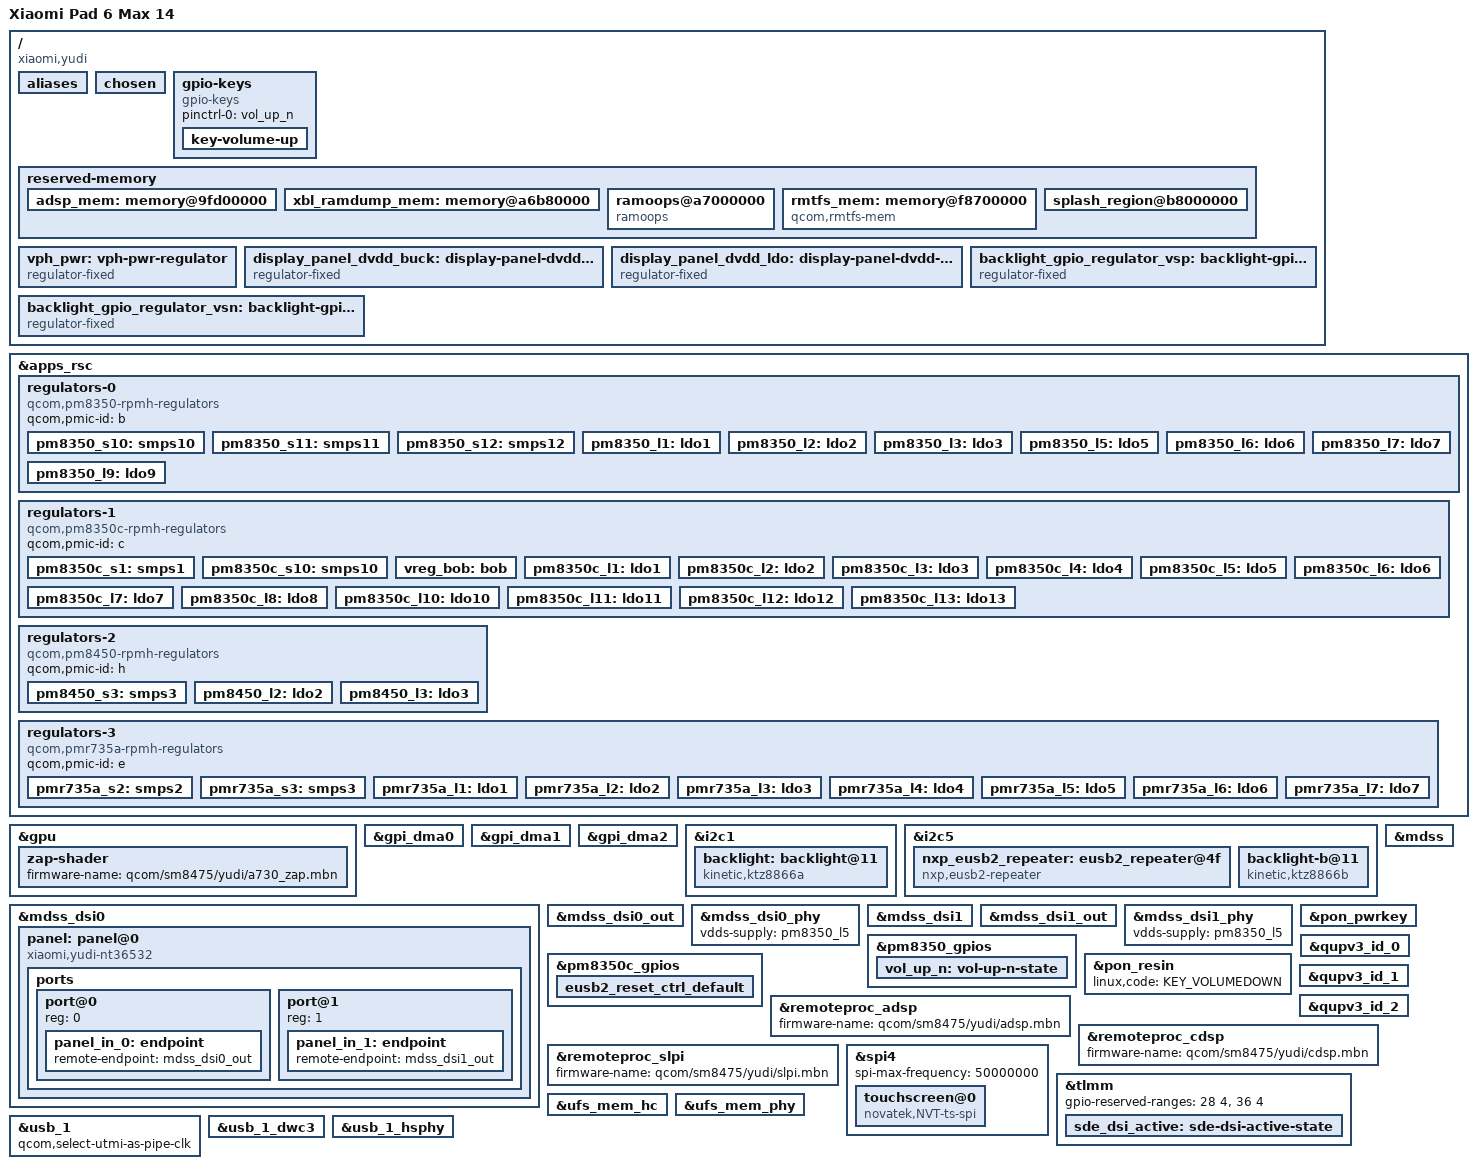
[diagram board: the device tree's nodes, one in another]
// SPDX-License-Identifier: GPL-2.0-only
/*
 * Copyright (c) 2025, The Linux Foundation. All rights reserved.
 * Copyright (c) 2025, Sophie 'Tyalie' Friedrich <kernel@flowerpot.me>
 */
/dts-v1/;

#include <dt-bindings/arm/qcom,ids.h>
#include <dt-bindings/pinctrl/qcom,pmic-gpio.h>
#include <dt-bindings/regulator/qcom,rpmh-regulator.h>
#include <dt-bindings/leds/common.h>
#include <dt-bindings/interrupt-controller/irq.h>

#include "sm8475.dtsi"
#include "pm8350.dtsi"
#include "pm8350b.dtsi"
#include "pm8350c.dtsi"
#include "pm8450.dtsi"
#include "pmk8350.dtsi"
#include "pmr735a.dtsi"

/delete-node/ &adsp_mem;
/delete-node/ &rmtfs_mem;
/delete-node/ &xbl_ramdump_mem;
/delete-node/ &xbl_sc_mem;

/ {
	model = "Xiaomi Pad 6 Max 14";
	compatible = "xiaomi,yudi", "qcom,sm8475";
	chassis-type = "tablet";

	aliases {
	};

	chosen {
		#address-cells = <2>;
		#size-cells = <2>;
		ranges;

		bootargs = "PMOS_NOSPLASH earlycon clk_ignore_unused pd_ignore_unused console=tty0";

	};


	gpio-keys {
		compatible = "gpio-keys";

		pinctrl-0 = <&vol_up_n>;
		pinctrl-names = "default";

		key-volume-up {
			label = "Volume Up";
			linux,code = <KEY_VOLUMEUP>;
			gpios = <&pm8350_gpios 6 GPIO_ACTIVE_LOW>;
			debounce-interval = <32>;
			linux,can-disable;
			wakeup-source;
		};
	};

	reserved-memory {
		adsp_mem: memory@9fd00000 {
			reg = <0x0 0x9fd00000 0x0 0x3100000>;
			no-map;
		};

		xbl_ramdump_mem: memory@a6b80000 {
			reg = <0x0 0xa6b80000 0x0 0x280000>;
			no-map;
		};

		ramoops@a7000000 {
			compatible = "ramoops";
			reg = <0x0 0xa7000000 0x0 0x400000>;

			record-size = <0x200000>;
			pmsg-size = <0x200000>;
			console-size = <0x200000>;
			no-map;
		};

		rmtfs_mem: memory@f8700000 {
			compatible = "qcom,rmtfs-mem";
			reg = <0x0 0xf8700000 0x0 0x280000>;
			no-map;

			qcom,client-id = <1>;
			qcom,vmid = <QCOM_SCM_VMID_MSS_MSA>;
		};


		splash_region@b8000000 {
			reg = <0x0 0xb8000000 0x0 0x2b00000>;
			no-map;
		};
	};

	vph_pwr: vph-pwr-regulator {
		compatible = "regulator-fixed";
		regulator-name = "vph_pwr";
		regulator-min-microvolt = <3700000>;
		regulator-max-microvolt = <3700000>;

		regulator-always-on;
		regulator-boot-on;
	};

	display_panel_dvdd_buck: display-panel-dvdd-buck {
		compatible = "regulator-fixed";
		regulator-name = "display_panel_dvdd_buck";
		regulator-min-microvolt = <(1300 * 1000)>;
		regulator-max-microvolt = <(1300 * 1000)>;
		gpio = <&tlmm 2 GPIO_ACTIVE_HIGH>;
		enable-active-high;
		regulator-boot-on;

		regulator-always-on;
	};

	display_panel_dvdd_ldo: display-panel-dvdd-ldo {
		compatible = "regulator-fixed";
		regulator-name = "display_panel_dvdd_ldo";
		regulator-min-microvolt = <(1300 * 1000)>;
		regulator-max-microvolt = <(1300 * 1000)>;
		gpio = <&tlmm 93 GPIO_ACTIVE_HIGH>;
		enable-active-high;
		regulator-boot-on;

		regulator-always-on;
	};

	backlight_gpio_regulator_vsp: backlight-gpio-reg-vsp {
		compatible = "regulator-fixed";
		regulator-name = "backlight_gpio_vsp";
		regulator-min-microvolt = <5500000>;
		regulator-max-microvolt = <5500000>;
		regulator-enable-ramp-delay = <233>;
		gpio = <&tlmm 66 GPIO_ACTIVE_HIGH>;
		enable-active-high;
		regulator-boot-on;

		regulator-always-on;
	};

	backlight_gpio_regulator_vsn: backlight-gpio-reg-vsn {
		compatible = "regulator-fixed";
		regulator-name = "backlight_gpio_vsn";
		regulator-min-microvolt = <5500000>;
		regulator-max-microvolt = <5500000>;
		regulator-enable-ramp-delay = <233>;
		gpio = <&tlmm 53 GPIO_ACTIVE_HIGH>;
		enable-active-high;
		regulator-boot-on;

		regulator-always-on;
	};
};

&apps_rsc {
	regulators-0 {
		compatible = "qcom,pm8350-rpmh-regulators";
		qcom,pmic-id = "b";

		/*
		vdd-s1-supply = <&vph_pwr>;
		vdd-s2-supply = <&vph_pwr>;
		vdd-s3-supply = <&vph_pwr>;
		vdd-s4-supply = <&vph_pwr>;
		vdd-s5-supply = <&vph_pwr>;
		vdd-s6-supply = <&vph_pwr>;
		vdd-s7-supply = <&vph_pwr>;
		vdd-s8-supply = <&vph_pwr>;
		vdd-s9-supply = <&vph_pwr>;
		vdd-s10-supply = <&vph_pwr>;
		vdd-s11-supply = <&vph_pwr>;
		vdd-s12-supply = <&vph_pwr>;

		vdd-l1-l4-supply = <&pm8350_s11>;
		vdd-l2-l7-supply = <&vreg_bob>;
		vdd-l3-l5-supply = <&pm8350_s11>;
		vdd-l6-l9-l10-supply = <&pm8350_s12>;
		*/

		/*
		 * ARC regulators:
		 * s5 - gfx.lvl
		 * l8 - lcx.lvl
		 */

		pm8350_s10: smps10 {
			regulator-name = "pm8350_s10";
			regulator-min-microvolt = <1800000>;
			regulator-max-microvolt = <1800000>;
		};

		pm8350_s11: smps11 {
			regulator-name = "pm8350_s11";
			regulator-min-microvolt = <382000>;
			regulator-max-microvolt = <1170000>;
		};

		pm8350_s12: smps12 {
			regulator-name = "pm8350_s12";
			regulator-min-microvolt = <1224000>;
			regulator-max-microvolt = <2040000>;
		};

		pm8350_l1: ldo1 {
			regulator-name = "pm8350_l1";
			regulator-min-microvolt = <830000>;
			regulator-max-microvolt = <920000>;
			regulator-initial-mode = <RPMH_REGULATOR_MODE_HPM>;
		};

		pm8350_l2: ldo2 {
			regulator-name = "pm8350_l2";
			regulator-min-microvolt = <2700000>;
			regulator-max-microvolt = <3300000>;
			regulator-initial-mode = <RPMH_REGULATOR_MODE_HPM>;
		};

		pm8350_l3: ldo3 {
			regulator-name = "pm8350_l3";
			regulator-min-microvolt = <870000>;
			regulator-max-microvolt = <970000>;
			regulator-initial-mode = <RPMH_REGULATOR_MODE_HPM>;
		};

		pm8350_l5: ldo5 {
			regulator-name = "pm8350_l5";
			regulator-min-microvolt = <720000>;
			regulator-max-microvolt = <958000>;
			regulator-initial-mode = <RPMH_REGULATOR_MODE_HPM>;
		};

		pm8350_l6: ldo6 {
			regulator-name = "pm8350_l6";
			regulator-min-microvolt = <1200000>;
			regulator-max-microvolt = <1216000>;
			regulator-initial-mode = <RPMH_REGULATOR_MODE_HPM>;
		};

		pm8350_l7: ldo7 {
			regulator-name = "pm8350_l7";
			regulator-min-microvolt = <2400000>;
			regulator-max-microvolt = <3544000>;
			regulator-initial-mode = <RPMH_REGULATOR_MODE_HPM>;
		};

		pm8350_l9: ldo9 {
			regulator-name = "pm8350_l9";
			regulator-min-microvolt = <1200000>;
			regulator-max-microvolt = <1304000>;
			regulator-initial-mode = <RPMH_REGULATOR_MODE_HPM>;
		};
	};

	regulators-1 {
		compatible = "qcom,pm8350c-rpmh-regulators";
		qcom,pmic-id = "c";

		/*
		vdd-s1-supply = <&vph_pwr>;
		vdd-s2-supply = <&vph_pwr>;
		vdd-s3-supply = <&vph_pwr>;
		vdd-s4-supply = <&vph_pwr>;
		vdd-s5-supply = <&vph_pwr>;
		vdd-s6-supply = <&vph_pwr>;
		vdd-s7-supply = <&vph_pwr>;
		vdd-s8-supply = <&vph_pwr>;
		vdd-s9-supply = <&vph_pwr>;
		vdd-s10-supply = <&vph_pwr>;

		vdd-l1-l12-supply = <&pm8350c_s1>;
		vdd-l2-l8-supply = <&pm8350c_s1>;
		vdd-l3-l4-l5-l7-l13-supply = <&vreg_bob>;
		vdd-l6-l9-l11-supply = <&vreg_bob>;
		vdd-l10-supply = <&pm8350_s12>;

		vdd-bob-supply = <&vph_pwr>;
		*/

		/*
		 * ARC regulators:
		 * s2 - mxc.lvl
		 * s4 - mss.lvl
		 * s6 - cx.lvl
		 */

		pm8350c_s1: smps1 {
			regulator-name = "pm8350c_s1";
			regulator-min-microvolt = <1800000>;
			regulator-max-microvolt = <2024000>;
		};

		pm8350c_s10: smps10 {
			regulator-name = "pm8350c_s10";
			regulator-min-microvolt = <1052000>;
			regulator-max-microvolt = <1170000>;
		};

		vreg_bob: bob {
			regulator-name = "vreg_bob";
			regulator-min-microvolt = <3008000>;
			regulator-max-microvolt = <3960000>;
			regulator-initial-mode = <RPMH_REGULATOR_MODE_AUTO>;
		};

		pm8350c_l1: ldo1 {
			regulator_name = "pm8350c_l1";
			regulator-min-microvolt = <1800000>;
			regulator-max-microvolt = <1800000>;
			regulator-initial-mode = <RPMH_REGULATOR_MODE_HPM>;
		};

		pm8350c_l2: ldo2 {
			regulator-name = "pm8350c_l2";
			regulator-min-microvolt = <1800000>;
			regulator-max-microvolt = <1980000>;
			regulator-initial-mode = <RPMH_REGULATOR_MODE_HPM>;
		};

		pm8350c_l3: ldo3 {
			regulator-name = "pm8350c_l3";
			regulator-min-microvolt = <2700000>;
			regulator-max-microvolt = <3544000>;
			regulator-initial-mode = <RPMH_REGULATOR_MODE_HPM>;
			regulator-boot-on;
			regulator-always-on;
		};

		pm8350c_l4: ldo4 {
			regulator-name = "pm8350c_l4";
			regulator-min-microvolt = <1620000>;
			regulator-max-microvolt = <3300000>;
			regulator-initial-mode = <RPMH_REGULATOR_MODE_HPM>;
		};

		pm8350c_l5: ldo5 {
			regulator-name = "pm8350c_l5";
			regulator-min-microvolt = <1620000>;
			regulator-max-microvolt = <3300000>;
			regulator-initial-mode = <RPMH_REGULATOR_MODE_HPM>;
		};

		pm8350c_l6: ldo6 {
			regulator-name = "pm8350c_l6";
			regulator-min-microvolt = <1800000>;
			regulator-max-microvolt = <3544000>;
			regulator-initial-mode = <RPMH_REGULATOR_MODE_HPM>;
		};

		pm8350c_l7: ldo7 {
			regulator-name = "pm8350c_l7";
			regulator-min-microvolt = <3000000>;
			regulator-max-microvolt = <3544000>;
			regulator-initial-mode = <RPMH_REGULATOR_MODE_HPM>;
		};

		pm8350c_l8: ldo8 {
			regulator-name = "pm8350c_l8";
			regulator-min-microvolt = <1800000>;
			regulator-max-microvolt = <2000000>;
			regulator-initial-mode = <RPMH_REGULATOR_MODE_HPM>;
		};

//		pm8350c_l9: ldo9 {
//			regulator-name = "pm8350c_l9";
//			regulator-min-microvolt = <3300000>;
//			regulator-max-microvolt = <3300000>;
//			regulator-initial-mode = <RPMH_REGULATOR_MODE_HPM>;
//		};

		pm8350c_l10: ldo10 {
			regulator-name = "pm8350c_l10";
			regulator-min-microvolt = <1200000>;
			regulator-max-microvolt = <1304000>;
			regulator-initial-mode = <RPMH_REGULATOR_MODE_HPM>;
		};

		pm8350c_l11: ldo11 {
			regulator-name = "pm8350c_l11";
			regulator-min-microvolt = <2400000>;
			regulator-max-microvolt = <3008000>;
			regulator-initial-mode = <RPMH_REGULATOR_MODE_HPM>;
		};

		pm8350c_l12: ldo12 {
			regulator-name = "pm8350c_l12";
			regulator-min-microvolt = <1800000>;
			regulator-max-microvolt = <1980000>;
			regulator-initial-mode = <RPMH_REGULATOR_MODE_HPM>;
		};

		pm8350c_l13: ldo13 {
			regulator-name = "pm8350c_l13";
			regulator-min-microvolt = <2700000>;
			regulator-max-microvolt = <3544000>;
			regulator-initial-mode = <RPMH_REGULATOR_MODE_HPM>;
		};
	};

	regulators-2 {
		compatible = "qcom,pm8450-rpmh-regulators";
		qcom,pmic-id = "h";

		/*
		vdd-s1-supply = <&vph_pwr>;
		vdd-s2-supply = <&vph_pwr>;
		vdd-s3-supply = <&vph_pwr>;
		vdd-s4-supply = <&vph_pwr>;
		vdd-s5-supply = <&vph_pwr>;
		vdd-s6-supply = <&vph_pwr>;

		vdd-l2-supply = <&vreg_bob>;
		vdd-l3-supply = <&vreg_bob>;
		vdd-l4-supply = <&vreg_bob>;
		*/

		/*
		 * ARC regulators:
		 * S2 - ebi.lvl
		 * S4 - mmcx.lvl
		 * S6 - mx.lvl
		 * L1 - lmx.lvl
		 */

		pm8450_s3: smps3 {
			regulator-name = "pm8450_s3";
			regulator-min-microvolt = <470000>;
			regulator-max-microvolt = <570000>;
		};

		pm8450_l2: ldo2 {
			regulator-name = "pm8450_l2";
			regulator-min-microvolt = <820000>;
			regulator-max-microvolt = <958000>;
			regulator-initial-mode = <RPMH_REGULATOR_MODE_HPM>;
		};

		pm8450_l3: ldo3 {
			regulator-name = "pm8450_l3";
			regulator-min-microvolt = <866000>;
			regulator-max-microvolt = <958000>;
			regulator-initial-mode = <RPMH_REGULATOR_MODE_HPM>;
		};
	};

	regulators-3 {
		compatible = "qcom,pmr735a-rpmh-regulators";
		qcom,pmic-id = "e";

		/*
		vdd-s1-supply = <&vph_pwr>;
		vdd-s2-supply = <&vph_pwr>;
		vdd-s3-supply = <&vph_pwr>;

		vdd-l1-l2-supply = <&pmr735a_s2>;
		vdd-l3-supply = <&pmr735a_s1>;
		vdd-l4-supply = <&pm8350c_s1>;
		vdd-l5-l6-supply = <&pm8350c_s1>;
		vdd-l7-bob-supply = <&vreg_bob>;
		*/

		pmr735a_s2: smps2 {
			regulator-name = "pmr735a_s2";
			regulator-min-microvolt = <500000>;
			regulator-max-microvolt = <1040000>;
		};

		pmr735a_s3: smps3 {
			regulator-name = "pmr735a_s3";
			regulator-min-microvolt = <300000>;
			regulator-max-microvolt = <2352000>;
		};

		pmr735a_l1: ldo1 {
			regulator-name = "pmr735a_l1";
			regulator-min-microvolt = <800000>;
			regulator-max-microvolt = <880000>;
		};

		pmr735a_l2: ldo2 {
			regulator-name = "pmr735a_l2";
			regulator-min-microvolt = <480000>;
			regulator-max-microvolt = <1200000>;
		};

		pmr735a_l3: ldo3 {
			regulator-name = "pmr735a_l3";
			regulator-min-microvolt = <1200000>;
			regulator-max-microvolt = <1200000>;
		};

		pmr735a_l4: ldo4 {
			regulator-name = "pmr735a_l4";
			regulator-min-microvolt = <1776000>;
			regulator-max-microvolt = <1776000>;
		};

		pmr735a_l5: ldo5 {
			regulator-name = "pmr735a_l5";
			regulator-min-microvolt = <880000>;
			regulator-max-microvolt = <920000>;
		};

		pmr735a_l6: ldo6 {
			regulator-name = "pmr735a_l6";
			regulator-min-microvolt = <1200000>;
			regulator-max-microvolt = <1200000>;
		};

		pmr735a_l7: ldo7 {
			regulator-name = "pmr735a_l7";
			regulator-min-microvolt = <2800000>;
			regulator-max-microvolt = <2800000>;
		};
	};
};

&gpu {
	status = "okay";

	zap-shader {
		firmware-name = "qcom/sm8475/yudi/a730_zap.mbn";
	};
};

&gpi_dma0 {
	status = "okay";
};

&gpi_dma1 {
	status = "okay";
};

&gpi_dma2 {
	status = "okay";
};

&i2c1 {
	status = "okay";

	/* ktz8866@11 ktz,ktz8866b */
	backlight: backlight@11 {
		compatible = "kinetic,ktz8866a";
		reg = <0x11>;
		vddpos-supply = <&backlight_gpio_regulator_vsp>;
		vddneg-supply = <&backlight_gpio_regulator_vsn>;
		enable-gpios = <&tlmm 6 GPIO_ACTIVE_HIGH>;
		current-num-sinks = <5>;
		kinetic,current-ramp-delay-ms = <128>;
		kinetic,led-enable-ramp-delay-ms = <1>;
		kinetic,enable-lcd-bias;

	};

};

&i2c5 {
	status = "okay";

	/* fsa4480@42 qcom,fsa4480-i2c */

	nxp_eusb2_repeater: eusb2_repeater@4f {
		compatible = "nxp,eusb2-repeater";
		reg = <0x4f>;
		vdd18-supply = <&pm8350_s10>;
		vdd3-supply = <&pm8350_l2>;
		reset-gpio = <&pm8350c_gpios 7 GPIO_ACTIVE_HIGH>;
		pinctrl-names = "default";
		pinctrl-0 = <&eusb2_reset_ctrl_default>;
		#phy-cells = <0>;
		qcom,param-override-seq = <0x40 0x06 0x01 0x07 0x65 0x08 0x03 0x0a>;
		qcom,param-override-seq-host = <0x30 0x06 0x00 0x07 0x64 0x08 0x03 0x0a>;
	};

	/* ktz8866@11 ktz,ktz8866b */
	backlight-b@11 {
		compatible = "kinetic,ktz8866b";
		reg = <0x11>;
		vddpos-supply = <&backlight_gpio_regulator_vsp>;
		vddneg-supply = <&backlight_gpio_regulator_vsn>;
		enable-gpios = <&tlmm 6 GPIO_ACTIVE_HIGH>;
		current-num-sinks = <5>;
		kinetic,current-ramp-delay-ms = <128>;
		kinetic,led-enable-ramp-delay-ms = <1>;
		kinetic,enable-lcd-bias;

	};
};

//&i2c9 {
//	clock-frequency = <1000000>;
//	status = "okay";
//
//	/* nq@28 qcom,sn-nci */
//};

//&spi13 {
//	clock-frequency = <50000000>;
//	status = "okay";
//
//	/* ir-spi@0 ir-spi */
//};

//&i2c15 {
//	clock-frequency = <1000000>;
//	status = "okay";
//
//	/* cs35l41@40 cirrus,cs35l41 */
//	/* cs35l41@42 cirrus,cs35l41 */
//};

&mdss {
	status = "okay";
};

&mdss_dsi0 {
	vdda-supply = <&pm8350c_l10>;
	qcom,dual-dsi-mode;
	qcom,sync-dual-dsi;
	qcom,master-dsi;

	status = "okay";

	panel: panel@0 {
		status = "okay";

		compatible = "xiaomi,yudi-nt36532", "novatek,nt36532";
		reg = <0>;

		vddio-supply = <&pm8350c_l2>;
		dvddbuck-supply = <&display_panel_dvdd_buck>;
		dvddldo-supply = <&display_panel_dvdd_ldo>;
		/*enp-supply = <&display_gpio_regulator_vsp>;
		enn-supply = <&display_gpio_regulator_vsn>; FIXME*/

		reset-gpios = <&tlmm 0 GPIO_ACTIVE_LOW>;
		backlight = <&backlight>;

		pinctrl-0 = <&sde_dsi_active>;
		pinctrl-names = "default";

		ports {
			#address-cells = <1>;
			#size-cells = <0>;

			port@0 {
				reg = <0>;
				panel_in_0: endpoint {
					remote-endpoint = <&mdss_dsi0_out>;
				};
			};

			port@1 {
				reg = <1>;
				panel_in_1: endpoint {
					remote-endpoint = <&mdss_dsi1_out>;
				};

			};
		};
	};
};

&mdss_dsi0_out {
	remote-endpoint = <&panel_in_0>;
	data-lanes = <0 1 2 3>;
};

&mdss_dsi0_phy {
	vdds-supply = <&pm8350_l5>;
	status = "okay";
};

&mdss_dsi1 {
	vdda-supply = <&pm8350c_l10>;
	qcom,dual-dsi-mode;
	qcom,sync-dual-dsi;
	assigned-clock-parents = <&mdss_dsi0_phy 0>, <&mdss_dsi0_phy 1>;
	status = "okay";
};

&mdss_dsi1_out {
	remote-endpoint = <&panel_in_1>;
	data-lanes = <0 1 2 3>;
};

&mdss_dsi1_phy {
	vdds-supply = <&pm8350_l5>;
	status = "okay";
};

&pm8350_gpios {
	vol_up_n: vol-up-n-state {
		pins = "gpio6";
		function = "normal";
		power-source = <1>;
		bias-pull-up;
	};
};

&pm8350c_gpios {
	eusb2_reset_ctrl_default: eusb2_reset_ctrl_default {
		pins = "gpio7";
		function = PMIC_GPIO_FUNC_NORMAL;
		input-enable;
		output-enable;
		bias-disable;
		power-source = <1>;	/* 1.8V */
		qcom,drive-strength = <PMIC_GPIO_STRENGTH_MED>;
	};
};

&pon_resin {
	linux,code = <KEY_VOLUMEDOWN>;
	status = "okay";
};

&pon_pwrkey {
	status = "okay";
};

&qupv3_id_0 {
	status = "okay";
};

&qupv3_id_1 {
	status = "okay";
};

&qupv3_id_2 {
	status = "okay";
};

&remoteproc_adsp {
	status = "okay";
	firmware-name = "qcom/sm8475/yudi/adsp.mbn";
};

&remoteproc_cdsp {
	status = "okay";
	firmware-name = "qcom/sm8475/yudi/cdsp.mbn";
};

&remoteproc_slpi {
	status = "okay";
	firmware-name = "qcom/sm8475/yudi/slpi.mbn";
};

&spi4 {
	status = "okay";
	spi-max-frequency = <50000000>;

	touchscreen@0 {
		compatible = "novatek,NVT-ts-spi";
		reg = <0>;

		spi-max-frequency = <9600000>;

		novatek,irq-gpio = <&tlmm 21 IRQ_TYPE_EDGE_RISING>;
		//novatek,swrst-n8-addr = <0x03F0FE>;
		novatek,swrst-n8-addr = <0x1fb43e>;

		novatek,pen-support;
		novatek,wgp-stylus;

		panel = <&panel>;

		firmware-name = "qcom/sm8475/yudi/novatek_nt36532_m80_fw_csot.bin";
	};
};

&tlmm {
	status = "okay";
	gpio-reserved-ranges = <28 4>, <36 4>;

	sde_dsi_active: sde-dsi-active-state {
		pins = "gpio0";
		function = "gpio";
		drive-strength = <8>;
		bias-disable;
	};
};


&ufs_mem_hc {
	status = "okay";

	reset-gpios = <&tlmm 210 GPIO_ACTIVE_LOW>;

	vcc-supply = <&pm8350_l7>;
	vcc-max-microamp = <1100000>;
	vccq-supply = <&pm8350_l9>;
	vccq-max-microamp = <1200000>;
};

&ufs_mem_phy {
	status = "okay";

	vdda-phy-supply = <&pm8350_l5>;
	vdda-pll-supply = <&pm8350c_l10>;
};

&usb_1 {
	/* USB 2.0 only */
	qcom,select-utmi-as-pipe-clk;
	status = "okay";
};

&usb_1_dwc3 {
	dr_mode = "peripheral";
	maximum-speed = "high-speed";
	/* Remove USB3 phy */
	phys = <&usb_1_hsphy>;
	phy-names = "usb2-phy";
};

&usb_1_hsphy {
	vdd-supply = <&pm8350_l5>;
	vdda12-supply = <&pm8350c_l10>;

	phys = <&nxp_eusb2_repeater>;

	status = "okay";
};
